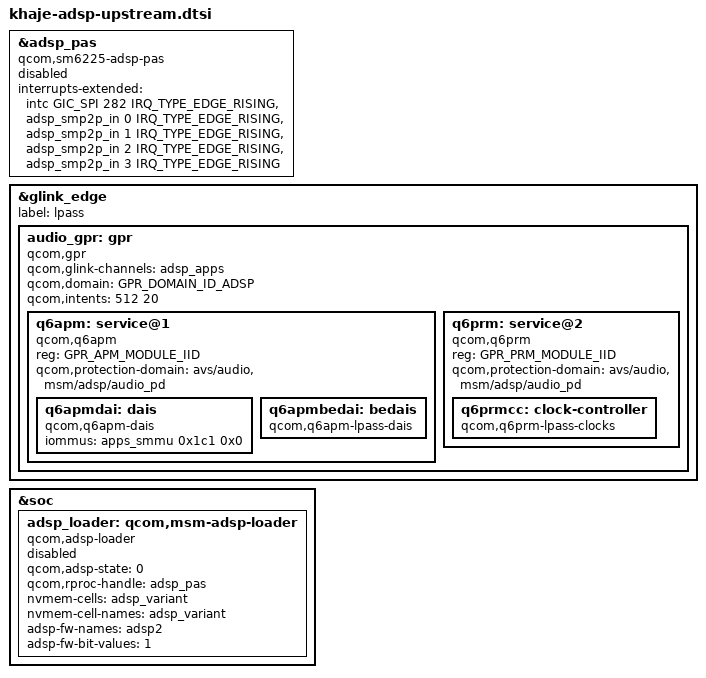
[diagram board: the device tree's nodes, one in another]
/* SPDX-License-Identifier: GPL-2.0-only */
/*
 * DTS DE TESTE — ADSP PAS upstream (qcom_q6v5_pas) para o Khaje/topaz.
 *
 * NAO e incluido por nenhuma DTS de producao e nao e encenado por
 * tools/integrate_dts.py (que so copia device-tree/source). Serve para
 * validar estaticamente o novo compatible qcom,sm6225-adsp-pas
 * (patch 0026) contra as labels reais da arvore encenada, sem ativar
 * probe nem boot do ADSP no Topaz. O no fica "disabled".
 *
 * Uso manual: incluir depois de khaje.dtsi/khaje-idp-nopmi.dtsi numa
 * DTS de teste e compilar com dtc. Auditoria em
 * docs/audio-port-audit.md.
 *
 * O que este fragmento faz sobre o no vendor adsp_pas da fonte:
 *   - troca qcom,khaje-adsp-pas por qcom,sm6225-adsp-pas;
 *   - remove somente neste prototipo as propriedades downstream de
 *     lista generica de reguladores (reg-names usado como nome de
 *     regulator e os pares *-uV-uA). Os supplies reais cx=L3A_LEVEL
 *     (VDD_LPI_CX) e mx=L2A_LEVEL (VDD_LPI_MX) sao preservados;
 *   - reordena os SMP2P para a ordem de nomes do binding upstream
 *     (fatal=bit0, ready=bit1, handover=bit2, stop-ack=bit3; o
 *     mapeamento nome<->bit e o mesmo do no vendor, so a lista muda);
 *   - ajusta o label do glink-edge para "lpass" e remove as
 *     propriedades de transporte especificas do vendor;
 *   - adiciona somente neste prototipo a cadeia GPR upstream
 *     (qcom,gpr -> qcom,q6apm/qcom,q6prm) sobre o canal
 *     "adsp_apps" e intents 512/20 do FDT. O no vendor guardava o
 *     dominio no reg do proprio qcom,gpr (lido assim pelo
 *     gpr-lite); aqui ele vira o qcom,domain explicito exigido
 *     pelo driver/binding upstream (ADSP=2);
 *   - modela o no qcom,adsp-loader do FDT, tambem desabilitado,
 *     para o driver do patch 0027: rproc-handle para &adsp_pas,
 *     celula adsp_variant e o par adsp2/bit 1 do overlay Bengal.
 *
 * Recursos herdados do no real/FDT:
 *   - reg 0xab00000/0x100, clock XO do RPMCC;
 *   - memory-region &pil_adsp_mem (fonte: 0x53800000/0x1e00000;
 *     FDT ativo: mesmo endereco com 0x2300000 — reconciliar);
 *   - watchdog GIC SPI 282, GLINK GIC SPI 277, mailbox apcs_glb 8 e
 *     qcom,remote-pid = <2>.
 *
 * Bloqueios conhecidos antes de qualquer ativacao:
 *   - o recurso do patch 0026 usa auto_boot=false, como o downstream.
 *     O patch 0027 adiciona um loader limpo para o contrato
 *     /sys/kernel/boot_adsp/{boot,ssr} que o init vendor escreve,
 *     delegando ao remoteproc generico e sem a dependencia
 *     spf_core_is_apm_ready() do driver vendor. Neste prototipo os
 *     nos PAS e loader seguem desabilitados;
 *   - o loader so aplica o nome escolhido pela adsp_variant quando
 *     ele e um arquivo completo .mdt/.mbn. O radical "adsp2" do
 *     Topaz mantem o default adsp.mdt do PAS, como no caminho
 *     efetivo do loader 5.15 (que nao aplicava o nome ao rproc).
 *     Caminho de busca e segmentos reais seguem sem hardware;
 *   - o PAS upstream consome cx e o segundo supply (px, ou mx pelo
 *     fallback do patch 0026); o patch 0028 agenda o nivel TURBO
 *     nesses rails para o recurso SM6225, traduzindo os
 *     reg-names/*-uV-uA downstream. O efeito desse corner no boot
 *     real segue sem validacao de hardware;
 *   - a cadeia GPR abaixo e um modelo upstream de substituicao,
 *     nao uma transcricao dos filhos vendor: o FDT usa portas de
 *     cliente spf_core=3, audio-pkt=0x17 e audio_prm=7, enquanto
 *     q6apm/q6prm upstream usam os IIDs estaticos 1/2. O par
 *     qcom,protection-domain "avs/audio"/"msm/adsp/audio_pd" vem
 *     do audio_pdr vendor. No Android vendor do Topaz quem responde
 *     o service locator e o servico userspace vendor.pd_mapper
 *     (/vendor/bin/pd-mapper); por isso nao se adiciona match de
 *     raiz Khaje/SM6225 ao PD-mapper em kernel. A coexistencia em
 *     runtime continua sem validacao de hardware;
 *   - o SID 0x1c1 do q6apm-dais vem do no qcom,msm-audio-ion do
 *     FDT (mask vendor 0xf); confirmar em hardware antes de usar
 *     para DMA de verdade. LPASS/macros/SoundWire vivem no
 *     fragmento separado e desabilitado khaje-lpass-upstream.dtsi;
 *     pinctrl LPI, WCD937x e o card Bengal continuam fora, logo
 *     nao ha ASoC funcional;
 *   - CDSP e MPSS ficam fora: este fragmento cobre so o ADSP.
 */

#include <dt-bindings/interrupt-controller/arm-gic.h>
#include <dt-bindings/interrupt-controller/irq.h>
#include <dt-bindings/soc/qcom,gpr.h>

&adsp_pas {
	compatible = "qcom,sm6225-adsp-pas";

	/delete-property/ reg-names;
	/delete-property/ qcom,vdd_lpi_cx-uV-uA;
	/delete-property/ mx-uV-uA;

	interrupts-extended = <&intc GIC_SPI 282 IRQ_TYPE_EDGE_RISING>,
			      <&adsp_smp2p_in 0 IRQ_TYPE_EDGE_RISING>,
			      <&adsp_smp2p_in 1 IRQ_TYPE_EDGE_RISING>,
			      <&adsp_smp2p_in 2 IRQ_TYPE_EDGE_RISING>,
			      <&adsp_smp2p_in 3 IRQ_TYPE_EDGE_RISING>;
	interrupt-names = "wdog", "fatal", "ready",
			  "handover", "stop-ack";

	status = "disabled";
};

&glink_edge {
	/delete-property/ transport;
	/delete-property/ mbox-names;
	/delete-property/ qcom,glink-label;

	label = "lpass";

	/* O canal APR legado vendor nao faz parte da cadeia GPR. */
	/delete-node/ qcom,apr_tal_rpmsg;

	audio_gpr: gpr {
		compatible = "qcom,gpr";
		qcom,glink-channels = "adsp_apps";
		qcom,domain = <GPR_DOMAIN_ID_ADSP>;
		qcom,intents = <512 20>;
		#address-cells = <1>;
		#size-cells = <0>;

		q6apm: service@1 {
			compatible = "qcom,q6apm";
			reg = <GPR_APM_MODULE_IID>;
			#sound-dai-cells = <0>;
			qcom,protection-domain = "avs/audio",
						 "msm/adsp/audio_pd";

			q6apmdai: dais {
				compatible = "qcom,q6apm-dais";
				iommus = <&apps_smmu 0x1c1 0x0>;
			};

			q6apmbedai: bedais {
				compatible = "qcom,q6apm-lpass-dais";
				#sound-dai-cells = <1>;
			};
		};

		q6prm: service@2 {
			compatible = "qcom,q6prm";
			reg = <GPR_PRM_MODULE_IID>;
			qcom,protection-domain = "avs/audio",
						 "msm/adsp/audio_pd";

			q6prmcc: clock-controller {
				compatible = "qcom,q6prm-lpass-clocks";
				#clock-cells = <2>;
			};
		};
	};
};

&soc {
	adsp_loader: qcom,msm-adsp-loader {
		compatible = "qcom,adsp-loader";
		qcom,adsp-state = <0>;
		qcom,rproc-handle = <&adsp_pas>;
		nvmem-cells = <&adsp_variant>;
		nvmem-cell-names = "adsp_variant";
		adsp-fw-names = "adsp2";
		adsp-fw-bit-values = <1>;
		status = "disabled";
	};
};
